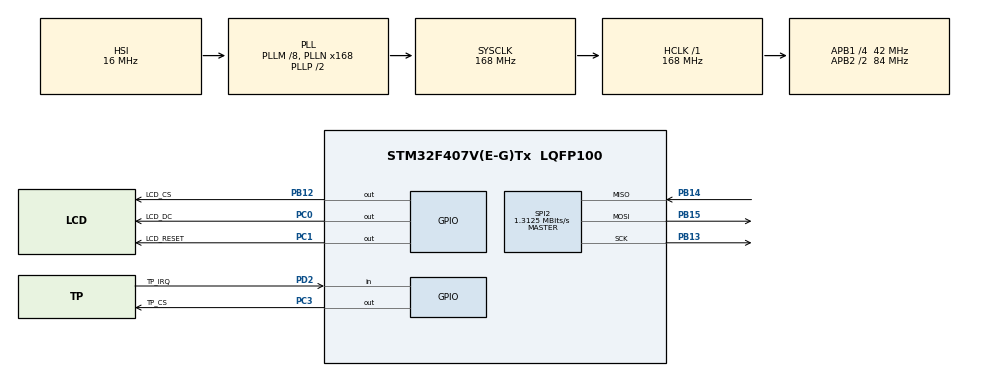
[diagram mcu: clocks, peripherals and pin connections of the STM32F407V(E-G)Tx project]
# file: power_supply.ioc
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Mcu.Family=STM32F4
Mcu.Name=STM32F407V(E-G)Tx
Mcu.Package=LQFP100
NVIC.PriorityGroup=NVIC_PRIORITYGROUP_4
PA13.Mode=Serial_Wire
PA13.Signal=SYS_JTMS-SWDIO
PA14.Mode=Serial_Wire
PA14.Signal=SYS_JTCK-SWCLK
PB12.GPIO_Label=LCD_CS
PB12.GPIO_ModeDefaultOutputPP=GPIO_MODE_OUTPUT_PP
PB12.GPIO_PuPd=GPIO_NOPULL
PB12.GPIO_Speed=GPIO_SPEED_FREQ_LOW
PB12.PinState=GPIO_PIN_SET
PB12.Signal=GPIO_Output
PB13.Mode=Full_Duplex_Master
PB13.Signal=SPI2_SCK
PB14.Mode=Full_Duplex_Master
PB14.Signal=SPI2_MISO
PB15.Mode=Full_Duplex_Master
PB15.Signal=SPI2_MOSI
PC0.GPIO_Label=LCD_DC
PC0.GPIO_ModeDefaultOutputPP=GPIO_MODE_OUTPUT_PP
PC0.GPIO_PuPd=GPIO_NOPULL
PC0.GPIO_Speed=GPIO_SPEED_FREQ_LOW
PC0.PinState=GPIO_PIN_RESET
PC0.Signal=GPIO_Output
PC1.GPIO_Label=LCD_RESET
PC1.GPIO_ModeDefaultOutputPP=GPIO_MODE_OUTPUT_PP
PC1.GPIO_PuPd=GPIO_NOPULL
PC1.GPIO_Speed=GPIO_SPEED_FREQ_LOW
PC1.PinState=GPIO_PIN_SET
PC1.Signal=GPIO_Output
PC3.GPIO_Label=TP_CS
PC3.GPIO_ModeDefaultOutputPP=GPIO_MODE_OUTPUT_PP
PC3.GPIO_PuPd=GPIO_NOPULL
PC3.GPIO_Speed=GPIO_SPEED_FREQ_LOW
PC3.PinState=GPIO_PIN_SET
PC3.Signal=GPIO_Output
PD2.GPIO_Label=TP_IRQ
PD2.GPIO_PuPd=GPIO_PULLUP
PD2.Signal=GPIO_Input
PH0-OSC_IN.Mode=HSE-External-Oscillator
PH0-OSC_IN.Signal=RCC_OSC_IN
PH1-OSC_OUT.Mode=HSE-External-Oscillator
PH1-OSC_OUT.Signal=RCC_OSC_OUT
ProjectManager.HeapSize=0x200
ProjectManager.StackSize=0x400
ProjectManager.TargetToolchain=CMake
RCC.48MHZClocksFreq_Value=84000000
RCC.AHBFreq_Value=168000000
RCC.APB1CLKDivider=RCC_HCLK_DIV4
RCC.APB1Freq_Value=42000000
RCC.APB1TimFreq_Value=84000000
RCC.APB2CLKDivider=RCC_HCLK_DIV2
RCC.APB2Freq_Value=84000000
RCC.APB2TimFreq_Value=168000000
RCC.CortexFreq_Value=168000000
RCC.HCLKFreq_Value=168000000
RCC.HSE_VALUE=25000000
RCC.HSI_VALUE=16000000
RCC.LSE_VALUE=32768
RCC.PLLM=8
RCC.PLLN=168
RCC.SYSCLKFreq_VALUE=168000000
RCC.SYSCLKSource=RCC_SYSCLKSOURCE_PLLCLK
RCC.VCOOutputFreq_Value=336000000
SPI2.BaudRatePrescaler=SPI_BAUDRATEPRESCALER_32
SPI2.CLKPhase=SPI_PHASE_1EDGE
SPI2.CLKPolarity=SPI_POLARITY_LOW
SPI2.CRCCalculation=SPI_CRCCALCULATION_DISABLE
SPI2.CalculateBaudRate=1.3125 MBits/s
SPI2.DataSize=SPI_DATASIZE_8BIT
SPI2.Direction=SPI_DIRECTION_2LINES
SPI2.FirstBit=SPI_FIRSTBIT_MSB
SPI2.Mode=SPI_MODE_MASTER
SPI2.NSS=SPI_NSS_SOFT
SPI2.TIMode=SPI_TIMODE_DISABLE
SPI2.VirtualType=VM_MASTER
board=custom

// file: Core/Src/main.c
/* USER CODE BEGIN Header */
/**
  ******************************************************************************
  * @file           : main.c
  * @brief          : Main program body
  ******************************************************************************
  * @attention
  *
  * Copyright (c) 2026 STMicroelectronics.
  * All rights reserved.
  *
  * This software is licensed under terms that can be found in the LICENSE file
  * in the root directory of this software component.
  * If no LICENSE file comes with this software, it is provided AS-IS.
  *
  ******************************************************************************
  */
/* USER CODE END Header */
#include "main.h"

/* USER CODE BEGIN Includes */
#include "display_app.h"
/* USER CODE END Includes */

SPI_HandleTypeDef hspi2;

void SystemClock_Config(void);
static void MX_GPIO_Init(void);
static void MX_SPI2_Init(void);

int main(void)
{

  /* MCU Configuration--------------------------------------------------------*/

  /* Reset of all peripherals, Initializes the Flash interface and the Systick. */
  HAL_Init();

  /* Configure the system clock */
  SystemClock_Config();

  /* Initialize all configured peripherals */
  MX_GPIO_Init();
  MX_SPI2_Init();
  /* USER CODE BEGIN 2 */
  if (DisplayApp_Init(&hspi2) != HAL_OK)
  {
    Error_Handler();
  }
  /* USER CODE END 2 */

  /* Infinite loop */
  while (1)
  {

    /* USER CODE BEGIN 3 */
    DisplayApp_Process();
  }
  /* USER CODE END 3 */
}

void SystemClock_Config(void)
{
  RCC_OscInitTypeDef RCC_OscInitStruct = {0};
  RCC_ClkInitTypeDef RCC_ClkInitStruct = {0};

  /** Configure the main internal regulator output voltage
  */
  __HAL_RCC_PWR_CLK_ENABLE();
  __HAL_PWR_VOLTAGESCALING_CONFIG(PWR_REGULATOR_VOLTAGE_SCALE1);

  /** Initializes the RCC Oscillators according to the specified parameters
  * in the RCC_OscInitTypeDef structure.
  */
  RCC_OscInitStruct.OscillatorType = RCC_OSCILLATORTYPE_HSI;
  RCC_OscInitStruct.HSIState = RCC_HSI_ON;
  RCC_OscInitStruct.HSICalibrationValue = RCC_HSICALIBRATION_DEFAULT;
  RCC_OscInitStruct.PLL.PLLState = RCC_PLL_ON;
  RCC_OscInitStruct.PLL.PLLSource = RCC_PLLSOURCE_HSI;
  RCC_OscInitStruct.PLL.PLLM = 8;
  RCC_OscInitStruct.PLL.PLLN = 168;
  RCC_OscInitStruct.PLL.PLLP = RCC_PLLP_DIV2;
  RCC_OscInitStruct.PLL.PLLQ = 4;
  if (HAL_RCC_OscConfig(&RCC_OscInitStruct) != HAL_OK)
  {
    Error_Handler();
  }

  /** Initializes the CPU, AHB and APB buses clocks
  */
  RCC_ClkInitStruct.ClockType = RCC_CLOCKTYPE_HCLK|RCC_CLOCKTYPE_SYSCLK
                              |RCC_CLOCKTYPE_PCLK1|RCC_CLOCKTYPE_PCLK2;
  RCC_ClkInitStruct.SYSCLKSource = RCC_SYSCLKSOURCE_PLLCLK;
  RCC_ClkInitStruct.AHBCLKDivider = RCC_SYSCLK_DIV1;
  RCC_ClkInitStruct.APB1CLKDivider = RCC_HCLK_DIV4;
  RCC_ClkInitStruct.APB2CLKDivider = RCC_HCLK_DIV2;

  if (HAL_RCC_ClockConfig(&RCC_ClkInitStruct, FLASH_LATENCY_5) != HAL_OK)
  {
    Error_Handler();
  }
}

static void MX_SPI2_Init(void)
{

  /* SPI2 parameter configuration*/
  hspi2.Instance = SPI2;
  hspi2.Init.Mode = SPI_MODE_MASTER;
  hspi2.Init.Direction = SPI_DIRECTION_2LINES;
  hspi2.Init.DataSize = SPI_DATASIZE_8BIT;
  hspi2.Init.CLKPolarity = SPI_POLARITY_LOW;
  hspi2.Init.CLKPhase = SPI_PHASE_1EDGE;
  hspi2.Init.NSS = SPI_NSS_SOFT;
  hspi2.Init.BaudRatePrescaler = SPI_BAUDRATEPRESCALER_32;
  hspi2.Init.FirstBit = SPI_FIRSTBIT_MSB;
  hspi2.Init.TIMode = SPI_TIMODE_DISABLE;
  hspi2.Init.CRCCalculation = SPI_CRCCALCULATION_DISABLE;
  hspi2.Init.CRCPolynomial = 10;
  if (HAL_SPI_Init(&hspi2) != HAL_OK)
  {
    Error_Handler();
  }

}

static void MX_GPIO_Init(void)
{
  GPIO_InitTypeDef GPIO_InitStruct = {0};

  /* GPIO Ports Clock Enable */
  __HAL_RCC_GPIOH_CLK_ENABLE();
  __HAL_RCC_GPIOC_CLK_ENABLE();
  __HAL_RCC_GPIOB_CLK_ENABLE();
  __HAL_RCC_GPIOA_CLK_ENABLE();
  __HAL_RCC_GPIOD_CLK_ENABLE();

  /*Configure GPIO pin Output Level */
  HAL_GPIO_WritePin(LCD_DC_GPIO_Port, LCD_DC_Pin, GPIO_PIN_RESET);

  /*Configure GPIO pin Output Level */
  HAL_GPIO_WritePin(GPIOC, LCD_RESET_Pin|TP_CS_Pin, GPIO_PIN_SET);

  /*Configure GPIO pin Output Level */
  HAL_GPIO_WritePin(LCD_CS_GPIO_Port, LCD_CS_Pin, GPIO_PIN_SET);

  /*Configure GPIO pins : LCD_DC_Pin LCD_RESET_Pin TP_CS_Pin */
  GPIO_InitStruct.Pin = LCD_DC_Pin|LCD_RESET_Pin|TP_CS_Pin;
  GPIO_InitStruct.Mode = GPIO_MODE_OUTPUT_PP;
  GPIO_InitStruct.Pull = GPIO_NOPULL;
  GPIO_InitStruct.Speed = GPIO_SPEED_FREQ_LOW;
  HAL_GPIO_Init(GPIOC, &GPIO_InitStruct);

  /*Configure GPIO pin : LCD_CS_Pin */
  GPIO_InitStruct.Pin = LCD_CS_Pin;
  GPIO_InitStruct.Mode = GPIO_MODE_OUTPUT_PP;
  GPIO_InitStruct.Pull = GPIO_NOPULL;
  GPIO_InitStruct.Speed = GPIO_SPEED_FREQ_LOW;
  HAL_GPIO_Init(LCD_CS_GPIO_Port, &GPIO_InitStruct);

  /*Configure GPIO pin : TP_IRQ_Pin */
  GPIO_InitStruct.Pin = TP_IRQ_Pin;
  GPIO_InitStruct.Mode = GPIO_MODE_INPUT;
  GPIO_InitStruct.Pull = GPIO_PULLUP;
  HAL_GPIO_Init(TP_IRQ_GPIO_Port, &GPIO_InitStruct);

}

void Error_Handler(void)
{
  __disable_irq();
  while (1)
  {
  }
}
